# colorlight register map
Vendor: litex
Registers are 32-bit, read-write, reset 0x0 unless marked. A register's access mark holds for its fields unless they carry their own. Offsets are from the block's base; [hi:lo] are bit positions; {n}, {i} and the like mark numbered series.

## CHAIN
Base 0xF0002000
0x00 FWD_FRAMES — Frames forwarded downstream (gray code)
  [15:0] fwd_frames
0x04 FWD_REWRITES — Discovery frames whose hop was incremented (gray code)
  [15:0] fwd_rewrites
0x08 FWD_DROPPED — Group-addressed frames NOT forwarded downstream (gray code)
  [15:0] fwd_dropped
0x0C UP_FRAMES — Frames queued upstream from port 1 (gray code)
  [15:0] up_frames
0x10 UP_DROPPED — Port 1 frames dropped: group-addressed, FIFO full or runt (gray code)
  [15:0] up_dropped

## PIXDMA
Base 0xF0002800
0x00 BASE — Derived framebuffer write address (read-only)
  [23:0] base
0x04 LIMIT — Pixels in the image; writes past this are dropped
  [23:0] limit
0x08 CTRL
  [0] enable — Enable hardware pixel writes
0x0C PIXELS — Pixels written
0x10 CHUNKS — Chunks accepted
0x14 BAD_MAGIC — Payloads rejected on magic
0x18 LAST_CHUNK — Most recent chunk_index
  [7:0] last_chunk
0x1C STATUS
  [0] busy — A payload is being written
0x20 STALLS — Payloads abandoned after a DRAM stall
0x24 STALL_PEAK — Longest run of consecutive cycles the writer spent in PIX without accepting a beat since the last peak_clear. Compare against stall_limit (8192); that value means it SATURATED.
  [15:0] stall_peak
0x28 PEAK_CLEAR — Write 1 to reset stall_peak, so it reads as a window
  [0] peak_clear
0x2C STALL_CYCLES — Total cycles spent in PIX without accepting a beat. Against pix_cycles this is the write path's blocked fraction.
0x30 PIX_CYCLES — Total cycles spent in PIX, the denominator for stall_cycles
0x34 THROTTLE — Idle cycles between pixel writes. 0 = full speed. Buys read bandwidth back for the scan-out, which has no row buffer.
  [3:0] throttle
0x38 BITMAP_SEL — Which 32-bit word of the chunk bitmaps `bitmap_arrival` and `bitmap_done` present. 0 is chunks 0-31, 15 is chunks 480-511.
  [3:0] bitmap_sel
0x3C BITMAP_ARRIVAL — The `bitmap_sel`-th word of the LIVE chunk arrival bitmap
0x40 BITMAP_DONE — The `bitmap_sel`-th word of the COMPLETED frame's bitmap
0x44 FRAME_ID — frame_id the arrival bitmap describes
  [15:0] frame_id
0x48 TOTAL_CHUNKS — total_chunks for frame_id
  [15:0] total_chunks
0x4C INDEXED — 1 if frame_id is indexed ('B','I'), 0 if RGB888
  [0] indexed
0x50 SWAP_WHOLE_ONLY reset 0x1 — 1 (default): request the hardware buffer swap only when the finishing frame received every chunk its header promised; an incomplete frame is held back and the last whole frame stays on the glass. 0: swap on every frame change as before, holes and all.
  [0] swap_whole_only
0x54 FRAMES_HELD — Frames NOT shown because they arrived incomplete. Each is a torn frame that would have reached the glass without swap_whole_only.
0x58 FRAME_ID_DONE — frame_id the completed bitmap describes
  [15:0] frame_id_done
0x5C TOTAL_CHUNKS_DONE — total_chunks of the completed frame
  [15:0] total_chunks_done
0x60 INDEXED_DONE — 1 if the completed frame was indexed
  [0] indexed_done
0x64 DONE_SEQ — Increments each time a frame is latched
  [15:0] done_seq

## XBARPERF
Base 0xF0003000
{0x0+4i} M{i} (i=0..5)

## CTRL
Base 0xF0003800
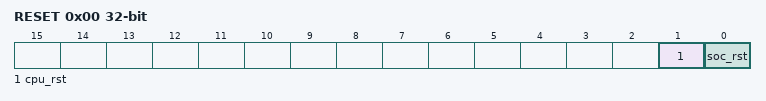
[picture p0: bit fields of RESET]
0x00 RESET
  [1] cpu_rst — Write `1` to this register to reset the CPU(s) of the SoC (Hold Reset)
  [0] soc_rst — Write `1` to this register to reset the full SoC (Pulse Reset)
0x04 SCRATCH reset 0x12345678 — Use this register as a scratch space to verify that software read/write accesses to the Wishbone/CSR bus are working correctly. The initial reset value of 0x12345678 can be used to verify endianness.
0x08 BUS_ERRORS — Total number of Wishbone bus errors (timeouts) since start.

## ETHPHY
Base 0xF0004800
0x00 CRG_RESET
  [0] crg_reset
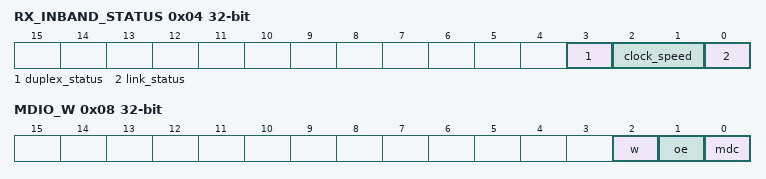
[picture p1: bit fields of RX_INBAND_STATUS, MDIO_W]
0x04 RX_INBAND_STATUS
  [3] duplex_status, [2:1] clock_speed, [0] link_status
0x08 MDIO_W
  [2] w, [1] oe, [0] mdc
0x0C MDIO_R
  [0] r
